AUTOSAR XML (schema 00049)
package /COM/VECTOR/CFG/WORKFLOW/SYSDESC/SYNC
  system SYSTEM: category=ECU_EXTRACT
    system mapping MAPPINGS
      data-mappings:
        data-element=COMPOSITIONTYPE.VcuRxMsg1_Sig0.VcuRxMsg1_Sig0, system-signal=VcuRxMsg1_Sig0
        data-element=COMPOSITIONTYPE.VcuRxMsg1_Sig2.VcuRxMsg1_Sig2, system-signal=VcuRxMsg1_Sig2
        data-element=COMPOSITIONTYPE.VcuRxMsg1_Sig1.VcuRxMsg1_Sig1, system-signal=VcuRxMsg1_Sig1
        data-element=COMPOSITIONTYPE.VcuRxMsg2_Sig3.VcuRxMsg2_Sig3, system-signal=VcuRxMsg2_Sig3
        data-element=COMPOSITIONTYPE.VcuRxMsg1_Sig3.VcuRxMsg1_Sig3, system-signal=VcuRxMsg1_Sig3
        data-element=COMPOSITIONTYPE.VcuRxMsg2_Sig0.VcuRxMsg2_Sig0, system-signal=VcuRxMsg2_Sig0
        data-element=COMPOSITIONTYPE.VcuRxMsg2_Sig2.VcuRxMsg2_Sig2, system-signal=VcuRxMsg2_Sig2
        data-element=COMPOSITIONTYPE.VcuRxMsg2_Sig1.VcuRxMsg2_Sig1, system-signal=VcuRxMsg2_Sig1
        data-element=COMPOSITIONTYPE.VcuTxMsg1_Sig1.VcuTxMsg1_Sig1, system-signal=VcuTxMsg1_Sig1
        data-element=COMPOSITIONTYPE.VcuTxMsg2_Sig1.VcuTxMsg2_Sig1, system-signal=VcuTxMsg2_Sig1
        data-element=COMPOSITIONTYPE.VcuTxMsg2_Sig2.VcuTxMsg2_Sig2, system-signal=VcuTxMsg2_Sig2
        data-element=COMPOSITIONTYPE.VcuTxMsg1_Sig3.VcuTxMsg1_Sig3, system-signal=VcuTxMsg1_Sig3
        data-element=COMPOSITIONTYPE.VcuTxMsg2_Sig0.VcuTxMsg2_Sig0, system-signal=VcuTxMsg2_Sig0
        data-element=COMPOSITIONTYPE.VcuTxMsg2_Sig3.VcuTxMsg2_Sig3, system-signal=VcuTxMsg2_Sig3
        data-element=COMPOSITIONTYPE.VcuTxMsg1_Sig2.VcuTxMsg1_Sig2, system-signal=VcuTxMsg1_Sig2
        data-element=COMPOSITIONTYPE.VcuTxMsg1_Sig0.VcuTxMsg1_Sig0, system-signal=VcuTxMsg1_Sig0
    root-software-compositions:
      root sw composition prototype COMPOSITIONTYPE: flat-map=FLATMAP, software-composition=COMPOSITIONTYPE
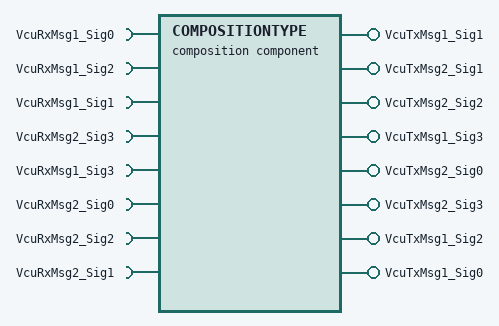
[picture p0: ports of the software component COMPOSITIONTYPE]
  composition sw component type COMPOSITIONTYPE  # UB:Derived from original system description
    8 x require port:
      VcuRxMsg1_Sig0: nonqueued-receiver-com-spec{data-element=VcuRxMsg1_Sig0, init-value=0}, required-interface=VcuRxMsg1_Sig0
      VcuRxMsg1_Sig2: nonqueued-receiver-com-spec{data-element=VcuRxMsg1_Sig2, init-value=0}, required-interface=VcuRxMsg1_Sig2
      VcuRxMsg1_Sig1: nonqueued-receiver-com-spec{data-element=VcuRxMsg1_Sig1, init-value=0}, required-interface=VcuRxMsg1_Sig1
      VcuRxMsg2_Sig3: nonqueued-receiver-com-spec{data-element=VcuRxMsg2_Sig3, init-value=0}, required-interface=VcuRxMsg2_Sig3
      VcuRxMsg1_Sig3: nonqueued-receiver-com-spec{data-element=VcuRxMsg1_Sig3, init-value=0}, required-interface=VcuRxMsg1_Sig3
      VcuRxMsg2_Sig0: nonqueued-receiver-com-spec{data-element=VcuRxMsg2_Sig0, init-value=0}, required-interface=VcuRxMsg2_Sig0
      VcuRxMsg2_Sig2: nonqueued-receiver-com-spec{data-element=VcuRxMsg2_Sig2, init-value=0}, required-interface=VcuRxMsg2_Sig2
      VcuRxMsg2_Sig1: nonqueued-receiver-com-spec{data-element=VcuRxMsg2_Sig1, init-value=0}, required-interface=VcuRxMsg2_Sig1
    8 x provide port:
      VcuTxMsg1_Sig1: nonqueued-sender-com-spec{data-element=VcuTxMsg1_Sig1, init-value=0}, provided-interface=VcuTxMsg1_Sig1
      VcuTxMsg2_Sig1: nonqueued-sender-com-spec{data-element=VcuTxMsg2_Sig1, init-value=0}, provided-interface=VcuTxMsg2_Sig1
      VcuTxMsg2_Sig2: nonqueued-sender-com-spec{data-element=VcuTxMsg2_Sig2, init-value=0}, provided-interface=VcuTxMsg2_Sig2
      VcuTxMsg1_Sig3: nonqueued-sender-com-spec{data-element=VcuTxMsg1_Sig3, init-value=0}, provided-interface=VcuTxMsg1_Sig3
      VcuTxMsg2_Sig0: nonqueued-sender-com-spec{data-element=VcuTxMsg2_Sig0, init-value=0}, provided-interface=VcuTxMsg2_Sig0
      VcuTxMsg2_Sig3: nonqueued-sender-com-spec{data-element=VcuTxMsg2_Sig3, init-value=0}, provided-interface=VcuTxMsg2_Sig3
      VcuTxMsg1_Sig2: nonqueued-sender-com-spec{data-element=VcuTxMsg1_Sig2, init-value=0}, provided-interface=VcuTxMsg1_Sig2
      VcuTxMsg1_Sig0: nonqueued-sender-com-spec{data-element=VcuTxMsg1_Sig0, init-value=0}, provided-interface=VcuTxMsg1_Sig0
    15 x component:
      BswM: type=BswM
      EcuM: type=EcuM
      Os_OsCore0_swc: type=Os_OsCore0_swc
      SWC1: type=SWC1
      ComM: type=ComM
      Det: type=Det
      PowerMng_SWC: type=PowerMng_SWC
      Com_SWC: type=Com_SWC
      NvM: type=NvM
      NvM_SWC: type=NvM_SWC
      DemMaster_0: type=DemMaster_0
      DemSatellite_0: type=DemSatellite_0
      Dcm: type=Dcm
      DIAG_SWC: type=DIAG_SWC
      IoHwAb_SWC: type=IoHwAb_SWC
    connect BswM.Switch_ESH_ModeSwitch -> BswM.Notification_ESH_ModeNotification
    connect SWC1.Request_ESH_RunRequest_0 -> BswM.Request_ESH_RunRequest_0
    connect ComM.UR_CN_TC37X_VCU_CAN00_b1b4f272 -> SWC1.UR_CN_TC37X_VCU_CAN00_b1b4f272
    delegate Com_SWC.VcuRxMsg1_Sig0 <-> outer port VcuRxMsg1_Sig0  # UB:Derived from original system description
    delegate Com_SWC.VcuRxMsg1_Sig2 <-> outer port VcuRxMsg1_Sig2  # UB:Derived from original system description
    delegate Com_SWC.VcuRxMsg1_Sig1 <-> outer port VcuRxMsg1_Sig1  # UB:Derived from original system description
    delegate Com_SWC.VcuRxMsg2_Sig3 <-> outer port VcuRxMsg2_Sig3  # UB:Derived from original system description
    delegate Com_SWC.VcuRxMsg1_Sig3 <-> outer port VcuRxMsg1_Sig3  # UB:Derived from original system description
    delegate Com_SWC.VcuRxMsg2_Sig0 <-> outer port VcuRxMsg2_Sig0  # UB:Derived from original system description
    delegate Com_SWC.VcuRxMsg2_Sig2 <-> outer port VcuRxMsg2_Sig2  # UB:Derived from original system description
    delegate Com_SWC.VcuRxMsg2_Sig1 <-> outer port VcuRxMsg2_Sig1  # UB:Derived from original system description
    delegate Com_SWC.VcuTxMsg1_Sig1 <-> outer port VcuTxMsg1_Sig1  # UB:Derived from original system description
    delegate Com_SWC.VcuTxMsg2_Sig1 <-> outer port VcuTxMsg2_Sig1  # UB:Derived from original system description
    delegate Com_SWC.VcuTxMsg2_Sig2 <-> outer port VcuTxMsg2_Sig2  # UB:Derived from original system description
    delegate Com_SWC.VcuTxMsg1_Sig3 <-> outer port VcuTxMsg1_Sig3  # UB:Derived from original system description
    delegate Com_SWC.VcuTxMsg2_Sig0 <-> outer port VcuTxMsg2_Sig0  # UB:Derived from original system description
    delegate Com_SWC.VcuTxMsg2_Sig3 <-> outer port VcuTxMsg2_Sig3  # UB:Derived from original system description
    delegate Com_SWC.VcuTxMsg1_Sig2 <-> outer port VcuTxMsg1_Sig2  # UB:Derived from original system description
    delegate Com_SWC.VcuTxMsg1_Sig0 <-> outer port VcuTxMsg1_Sig0  # UB:Derived from original system description
    connect SWC1.NvM_Data_IF_UserData1_Send -> NvM_SWC.NvM_Data_IF_UserData1_Recv  # UB:Derived from original system description
    connect NvM_SWC.NvM_Data_IF_UserData1_Send -> SWC1.NvM_Data_IF_UserData1_Recv  # UB:Derived from original system description
    connect SWC1.NvSWC_NvMNotifyJobFinished_UserData1 -> NvM_SWC.NvSWC_NvMNotifyJobFinished_NVBlockDescriptor_UserData1  # UB:Derived from original system description
    connect SWC1.NvM_Data_IF_UserData2_Send -> NvM_SWC.NvM_Data_IF_UserData2_Rcev  # UB:Derived from original system description
    connect NvM_SWC.NvM_Data_IF_UserData2_Send -> SWC1.NvM_Data_IF_UserData2_Recv  # UB:Derived from original system description
    connect SWC1.NvSWC_NvMNotifyJobFinished_UserData2 -> NvM_SWC.NvSWC_NvMNotifyJobFinished_NVBlockDescriptor_UserData2  # UB:Derived from original system description
    connect NvM.PS_SWC1NvBlockNeed_UserData3 -> SWC1.NvMService_AC3_SRBS_NvBlockNeed_UserData3
    connect NvM_SWC.NvMService_NVBlockDescriptor_UserData2 -> SWC1.NvSWC_UserData2_NvMService_AC3_SRBS  # UB:Derived from original system description
    connect DIAG_SWC.DataServices_VCU_DID_00_DataRecord -> Dcm.DataServices_VCU_DID_00_DataRecord
    connect NvM.PS_DIAG_SWC_NvBlockNeed_DiagDID_00 -> DIAG_SWC.PS_DIAG_SWC_NvBlockNeed_DiagDID_00
    connect DIAG_SWC.RoutineServices_Vcu_Roution_00 -> Dcm.RoutineServices_Vcu_Roution_00
    connect ComM.UR_CN_TC37X_VCU_CAN01_5e76994c -> SWC1.UR_CN_TC37X_VCU_CAN01_5e76994c
  end to end protection set E2EPROTECTIONSET
  port interface mapping set PORTINTERFACEMAPPINGSET
